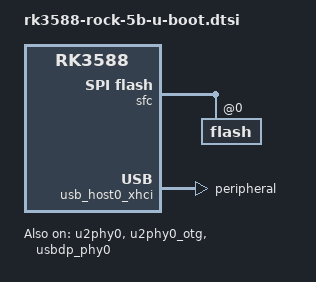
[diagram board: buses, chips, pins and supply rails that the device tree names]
// SPDX-License-Identifier: (GPL-2.0+ OR MIT)
/*
 * Copyright (c) 2023 Collabora Ltd.
 */

#include "rk3588-u-boot.dtsi"

&fspim2_pins {
	bootph-pre-ram;
	bootph-some-ram;
};

&sdhci {
	cap-mmc-highspeed;
	mmc-hs200-1_8v;
};

&sfc {
	flash@0 {
		bootph-pre-ram;
		bootph-some-ram;
	};
};

&u2phy0 {
	status = "okay";
};

&u2phy0_otg {
	status = "okay";
};

&usbdp_phy0 {
	status = "okay";
};

&usb_host0_xhci {
	dr_mode = "peripheral";
	maximum-speed = "high-speed";
	status = "okay";
};
